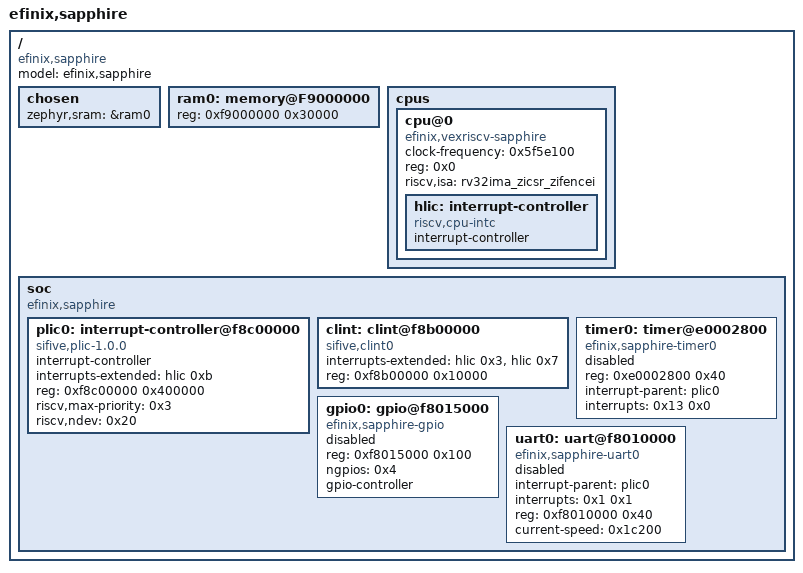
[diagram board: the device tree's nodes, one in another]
/dts-v1/;

/ {
	#address-cells = < 0x1 >;
	#size-cells = < 0x1 >;
	model = "efinix,sapphire";
	compatible = "efinix,sapphire";
	chosen {
		zephyr,sram = &ram0;
	};
	ram0: memory@F9000000 {
		device_type = "memory";
		reg = < 0xf9000000 0x30000 >;
	};
	cpus {
		#address-cells = < 0x1 >;
		#size-cells = < 0x0 >;
		cpu@0 {
			clock-frequency = < 0x5f5e100 >;
			compatible = "efinix,vexriscv-sapphire", "riscv";
			device_type = "cpu";
			reg = < 0x0 >;
			riscv,isa = "rv32ima_zicsr_zifencei";
			status = "okay";
			hlic: interrupt-controller {
				compatible = "riscv,cpu-intc";
				#address-cells = < 0x0 >;
				#interrupt-cells = < 0x1 >;
				interrupt-controller;
				phandle = < 0x1 >;
			};
		};
	};
	soc {
		#address-cells = < 0x1 >;
		#size-cells = < 0x1 >;
		compatible = "efinix,sapphire";
		ranges;
		plic0: interrupt-controller@f8c00000 {
			compatible = "sifive,plic-1.0.0";
			#address-cells = < 0x0 >;
			#interrupt-cells = < 0x2 >;
			interrupt-controller;
			interrupts-extended = < &hlic 0xb >;
			reg = < 0xf8c00000 0x400000 >;
			riscv,max-priority = < 0x3 >;
			riscv,ndev = < 0x20 >;
			phandle = < 0x2 >;
		};
		clint: clint@f8b00000 {
			compatible = "sifive,clint0";
			interrupts-extended = < &hlic 0x3 &hlic 0x7 >;
			reg = < 0xf8b00000 0x10000 >;
		};
		timer0: timer@e0002800 {
			compatible = "efinix,sapphire-timer0";
			reg = < 0xe0002800 0x40 >;
			interrupt-parent = < &plic0 >;
			interrupts = < 0x13 0x0 >;
			status = "disabled";
		};
		gpio0: gpio@f8015000 {
			compatible = "efinix,sapphire-gpio";
			reg = < 0xf8015000 0x100 >;
			reg-names = "base";
			ngpios = < 0x4 >;
			gpio-controller;
			#gpio-cells = < 0x2 >;
			#address-cells = < 0x1 >;
			#size-cells = < 0x1 >;
			status = "disabled";
		};
		uart0: uart@f8010000 {
			compatible = "efinix,sapphire-uart0";
			interrupt-parent = < &plic0 >;
			interrupts = < 0x1 0x1 >;
			reg = < 0xf8010000 0x40 >;
			reg-names = "base";
			current-speed = < 0x1c200 >;
			status = "disabled";
		};
	};
};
